# R7FA8M1AH register map
Vendor: Renesas; Series: RA8; File version: 1.2
CPU: CM85 r0p0, little endian, MPU, FPU, VTOR, 4 interrupt priority bits
Registers are 32-bit, read-write, reset 0x0 unless marked. A register's access mark holds for its fields unless they carry their own. Offsets are from the block's base; [hi:lo] are bit positions.

## ULPT0 — Ultra-Low Power Timer 0
Base 0x40220000
Same registers: ULPT1 0x40220100, ULPT0_NS 0x50220000, ULPT1_NS 0x50220100
0x00 ULPTCNT reset 0xFFFFFFFF — ULPT Counter Register
  [31:0] ULPTCNT — 32bit counter and reload registerNOTE : When 1 is written to the TSTOP bit in the ULPTCR register, the 32-bit counter is forcibly stopped and set to FFFFFFFFH.
0x04 ULPTCMA reset 0xFFFFFFFF — ULPT Compare Match A Register
  [31:0] ULPTCMA — ULPT Compare Match A RegisterNOTE : When 1 is written to the TSTOP bit in the ULPTCR register, set to FFFFFFFFH
0x08 ULPTCMB reset 0xFFFFFFFF — ULPT Compare Match B Register
  [31:0] ULPTCMB — AGT Compare Match B RegisterNOTE : When 1 is written to the TSTOP bit in the ULPTCR register, set to FFFFFFFFH
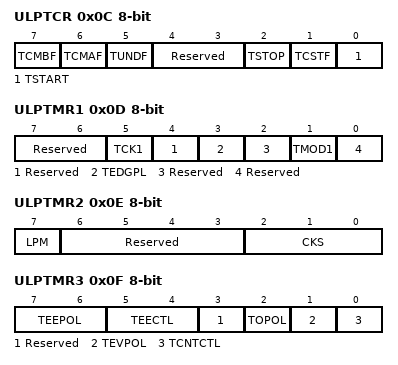
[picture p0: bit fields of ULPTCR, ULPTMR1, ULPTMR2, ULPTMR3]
0x0C ULPTCR 8-bit — ULPT Control Register
  [7] TCMBF write-0-clears read-modifies — ULPT compare match B flag
    0=No Match; 1=Match
  [6] TCMAF write-0-clears read-modifies — ULPT compare match A flag
    0=No Match; 1=Match
  [5] TUNDF write-0-clears read-modifies — ULPT underflow flag
    0=No underflow; 1=Underflow
  [4:3] Reserved — These bits are read as 00. The write value should be 00.
  [2] TSTOP wo — ULPT count forced stop
    0=no effect; 1=The count is forcibly stopped
  [1] TCSTF ro — ULPT count status flag
    0=Count stops; 1=Count running
  [0] TSTART — ULPT count start
    0=Count stops; 1=Count starts
0x0D ULPTMR1 8-bit — ULPT Mode Register 1
  [7:6] Reserved — These bits are read as 00. The write value should be 00.
  [5] TCK1 — ULPT count source select
    0=Divided clock LOCO specified by ULPTMR2.CKS bit; 1=Divided clock fSUB specified by ULPTMR2.CKS bit
  [4] Reserved — This bit is read as 0. The write value should be 0.
  [3] TEDGPL — ULPTEVI edge polarity select
    0=One edge(rise); 1=Both edges
  [2] Reserved — This bit is read as 0. The write value should be 0.
  [1] TMOD1 — ULPT operating mode select
    0=Timer mode; 1=Event counter mode
  [0] Reserved — This bit is read as 0. The write value should be 0.
0x0E ULPTMR2 8-bit — ULPT Mode Register 2
  [7] LPM — ULPT Low Power Mode
    0=Normal mode; 1=Low Power mode
  [6:3] Reserved — These bits are read as 0000. The write value should be 0000.
  [2:0] CKS — fsub/LOCO count source clock frequency division ratio select
    0=1/1; 1=1/2; 2=1/4; 3=1/8; 4=1/16; 5=1/32; 6=1/64; 7=1/128
0x0F ULPTMR3 8-bit — ULPT Mode Register 3
  [7:6] TEEPOL — ULPTEE edge polarity select
    0=Rise edge; 1=Fall edge; 2=Both edges; other=others (Setting prohibited)
  [5:4] TEECTL — ULPTEE function select
    0=Count enable mode; 2=Count start mode; 3=Count restart mode; other=others (Setting prohibited)
  [3] Reserved — This bit is read as 0. The write value should be 0.
  [2] TOPOL — ULPTO polarity select
    0=ULPTO Output is started at low; 1=ULPTO Output is started at high
  [1] TEVPOL — ULPTEVI polarity switch
    0=Extarnal event input(ULPTEVI port) forward rotation; 1=Extarnal event input(ULPTEVI port) inversion
  [0] TCNTCTL — ULPT count function select
    0=Continuous mode; 1=One shot mode
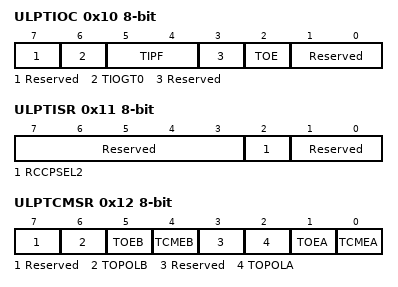
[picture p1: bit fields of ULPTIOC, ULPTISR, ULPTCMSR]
0x10 ULPTIOC 8-bit — ULPT I/O Control Register
  [7] Reserved — This bit is read as 0. The write value should be 0.
  [6] TIOGT0 — ULPTEVI count control
    0=Extarnal event is always counted; 1=Extarnal event is counted while the ULPTEE pin is active
  [5:4] TIPF — ULPTEVI input filter select
    0=No filter; 1=Filter sampled at PCLKB; 2=Filter sampled at PCLKB/8; 3=Filter sampled at PCLKB/32
  [3] Reserved — This bit is read as 0. The write value should be 0.
  [2] TOE — ULPTO output enable
    0=ULPTO output disabled (port); 1=ULPTO output enabled
  [1:0] Reserved — These bits are read as 00. The write value should be 00.
0x11 ULPTISR 8-bit — ULPT Event Pin Select Register
  [7:3] Reserved — These bits are read as 00000. The write value should be 00000.
  [2] RCCPSEL2 — ULPTEE polarty selection
    0=An external event is counted during the low-level period; 1=An external event is counted during the high-level period
  [1:0] Reserved — These bits are read as 00. The write value should be 00.
0x12 ULPTCMSR 8-bit — ULPT Compare Match Function Select Register
  [7] Reserved — This bit is read as 0. The write value should be 0.
  [6] TOPOLB — ULPTOB polarity select
    0=ULPTOB Output is started at low; 1=ULPTOB Output is started at high
  [5] TOEB — ULPTOB output enable
    0=ULPTOB output disabled (port); 1=ULPTOB output enabled
  [4] TCMEB — Compare match B register enable
    0=Disable compare match B register; 1=Enable compare match B register
  [3] Reserved — This bit is read as 0. The write value should be 0.
  [2] TOPOLA — ULPTOA polarity select
    0=ULPTOA Output is started at low; 1=ULPTOA Output is started at high
  [1] TOEA — ULPTOA output enable
    0=ULPTOA output disabled (port); 1=ULPTOA output enabled
  [0] TCMEA — Compare match A register enable
    0=Disable compare match A register; 1=Enable compare match A register
